# STM32F100xx register map
File version: 1.1
Registers are 32-bit, read-write, reset 0x0 unless marked. A register's access mark holds for its fields unless they carry their own. Offsets are from the block's base; [hi:lo] are bit positions.

## TIM13 — General purpose timer
Base 0x40001C00
Same registers: TIM14 0x40002000
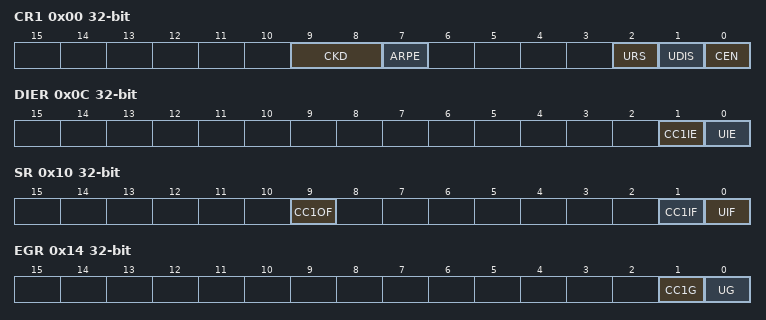
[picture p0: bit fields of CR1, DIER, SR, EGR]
0x00 CR1 — control register 1
  [9:8] CKD — Clock division
  [7] ARPE — Auto-reload preload enable
  [2] URS — Update request source
  [1] UDIS — Update disable
  [0] CEN — Counter enable
0x0C DIER — DMA/Interrupt enable register
  [1] CC1IE — Capture/Compare 1 interrupt enable
  [0] UIE — Update interrupt enable
0x10 SR — status register
  [9] CC1OF — Capture/Compare 1 overcapture flag
  [1] CC1IF — Capture/compare 1 interrupt flag
  [0] UIF — Update interrupt flag
0x14 EGR wo — event generation register
  [1] CC1G — Capture/compare 1 generation
  [0] UG — Update generation
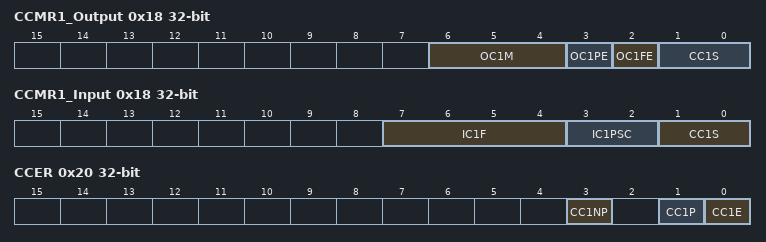
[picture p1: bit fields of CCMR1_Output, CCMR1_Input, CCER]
0x18 CCMR1_Output — capture/compare mode register (output mode)
  [6:4] OC1M — Output Compare 1 mode
  [3] OC1PE — Output Compare 1 preload enable
  [2] OC1FE — Output compare 1 fast enable
  [1:0] CC1S — Capture/Compare 1 selection
0x18 CCMR1_Input (alternate view of CCMR1_Output) — capture/compare mode register (input mode)
  [7:4] IC1F — Input capture 1 filter
  [3:2] IC1PSC — Input capture 1 prescaler
  [1:0] CC1S — Capture/Compare 1 selection
0x20 CCER — capture/compare enable register
  [3] CC1NP — Capture/Compare 1 output Polarity
  [1] CC1P — Capture/Compare 1 output Polarity
  [0] CC1E — Capture/Compare 1 output enable
0x24 CNT — counter
  [15:0] CNT — counter value
0x28 PSC — prescaler
  [15:0] PSC — Prescaler value
0x2C ARR — auto-reload register
  [15:0] ARR — Auto-reload value
0x34 CCR1 — capture/compare register 1
  [15:0] CCR1 — Capture/Compare 1 value

## TIM6 — Basic timer
Base 0x40001000
Same registers: TIM7 0x40001400
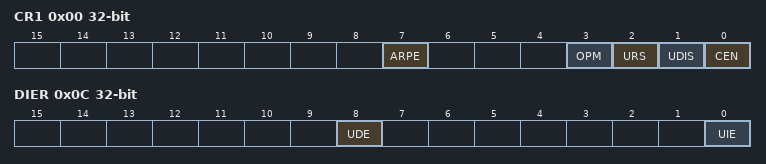
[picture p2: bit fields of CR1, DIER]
0x00 CR1 — control register 1
  [7] ARPE — Auto-reload preload enable
  [3] OPM — One-pulse mode
    0=Continuous (Counter is not stopped at update event); 1=OnePulse (Counter stops counting at the next update event (clearing the CEN bit))
  [2] URS — Update request source
  [1] UDIS — Update disable
  [0] CEN — Counter enable
    0=Disabled (Counter disabled); 1=Enabled (Counter enabled)
0x04 CR2 — control register 2
  [6:4] MMS — Master mode selection
0x0C DIER — DMA/Interrupt enable register
  [8] UDE — Update DMA request enable
  [0] UIE — Update interrupt enable
0x10 SR — status register
  [0] UIF — Update interrupt flag
    on read: 0=No update occurred; 1=Pending (Update interrupt pending) | on write: 0=Clears the update interrupt flag
0x14 EGR wo — event generation register
  [0] UG — Update generation
0x24 CNT — counter
  [15:0] CNT — Low counter value
0x28 PSC — prescaler
  [15:0] PSC — Prescaler value
0x2C ARR — auto-reload register
  [15:0] ARR — Low Auto-reload value

## I2C1 — Inter integrated circuit
Base 0x40005400
Same registers: I2C2 0x40005800
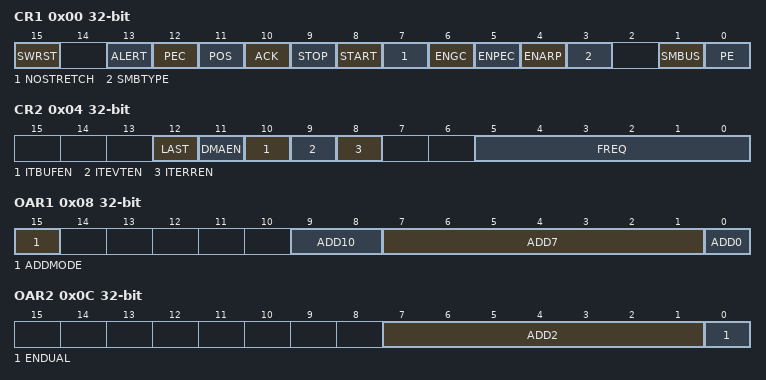
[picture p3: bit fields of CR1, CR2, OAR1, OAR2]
0x00 CR1 — Control register 1
  [15] SWRST — Software reset
  [13] ALERT — SMBus alert
  [12] PEC — Packet error checking
  [11] POS — Acknowledge/PEC Position (for data reception)
  [10] ACK — Acknowledge enable
  [9] STOP — Stop generation
  [8] START — Start generation
  [7] NOSTRETCH — Clock stretching disable (Slave mode)
  [6] ENGC — General call enable
  [5] ENPEC — PEC enable
  [4] ENARP — ARP enable
  [3] SMBTYPE — SMBus type
  [1] SMBUS — SMBus mode
  [0] PE — Peripheral enable
0x04 CR2 — Control register 2
  [12] LAST — DMA last transfer
  [11] DMAEN — DMA requests enable
  [10] ITBUFEN — Buffer interrupt enable
  [9] ITEVTEN — Event interrupt enable
  [8] ITERREN — Error interrupt enable
  [5:0] FREQ — Peripheral clock frequency
0x08 OAR1 — Own address register 1
  [15] ADDMODE — Addressing mode (slave mode)
  [9:8] ADD10 — Interface address
  [7:1] ADD7 — Interface address
  [0] ADD0 — Interface address
0x0C OAR2 — Own address register 2
  [7:1] ADD2 — Interface address
  [0] ENDUAL — Dual addressing mode enable
0x10 DR — Data register
  [7:0] DR — 8-bit data register
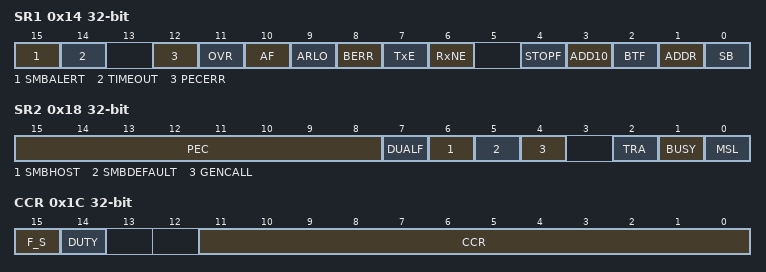
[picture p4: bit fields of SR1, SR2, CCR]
0x14 SR1 access per field — Status register 1
  [15] SMBALERT rw — SMBus alert
  [14] TIMEOUT rw — Timeout or Tlow error
  [12] PECERR rw — PEC Error in reception
  [11] OVR rw — Overrun/Underrun
  [10] AF rw — Acknowledge failure
  [9] ARLO rw — Arbitration lost (master mode)
  [8] BERR rw — Bus error
  [7] TxE ro — Data register empty (transmitters)
  [6] RxNE ro — Data register not empty (receivers)
  [4] STOPF ro — Stop detection (slave mode)
  [3] ADD10 ro — 10-bit header sent (Master mode)
  [2] BTF ro — Byte transfer finished
  [1] ADDR ro — Address sent (master mode)/matched (slave mode)
  [0] SB ro — Start bit (Master mode)
0x18 SR2 ro — Status register 2
  [15:8] PEC — acket error checking register
  [7] DUALF — Dual flag (Slave mode)
  [6] SMBHOST — SMBus host header (Slave mode)
  [5] SMBDEFAULT — SMBus device default address (Slave mode)
  [4] GENCALL — General call address (Slave mode)
  [2] TRA — Transmitter/receiver
  [1] BUSY — Bus busy
  [0] MSL — Master/slave
0x1C CCR — Clock control register
  [15] F_S — I2C master mode selection
  [14] DUTY — Fast mode duty cycle
  [11:0] CCR — Clock control register in Fast/Standard mode (Master mode)
0x20 TRISE reset 0x2
  [5:0] TRISE — Maximum rise time in Fast/Standard mode (Master mode)
